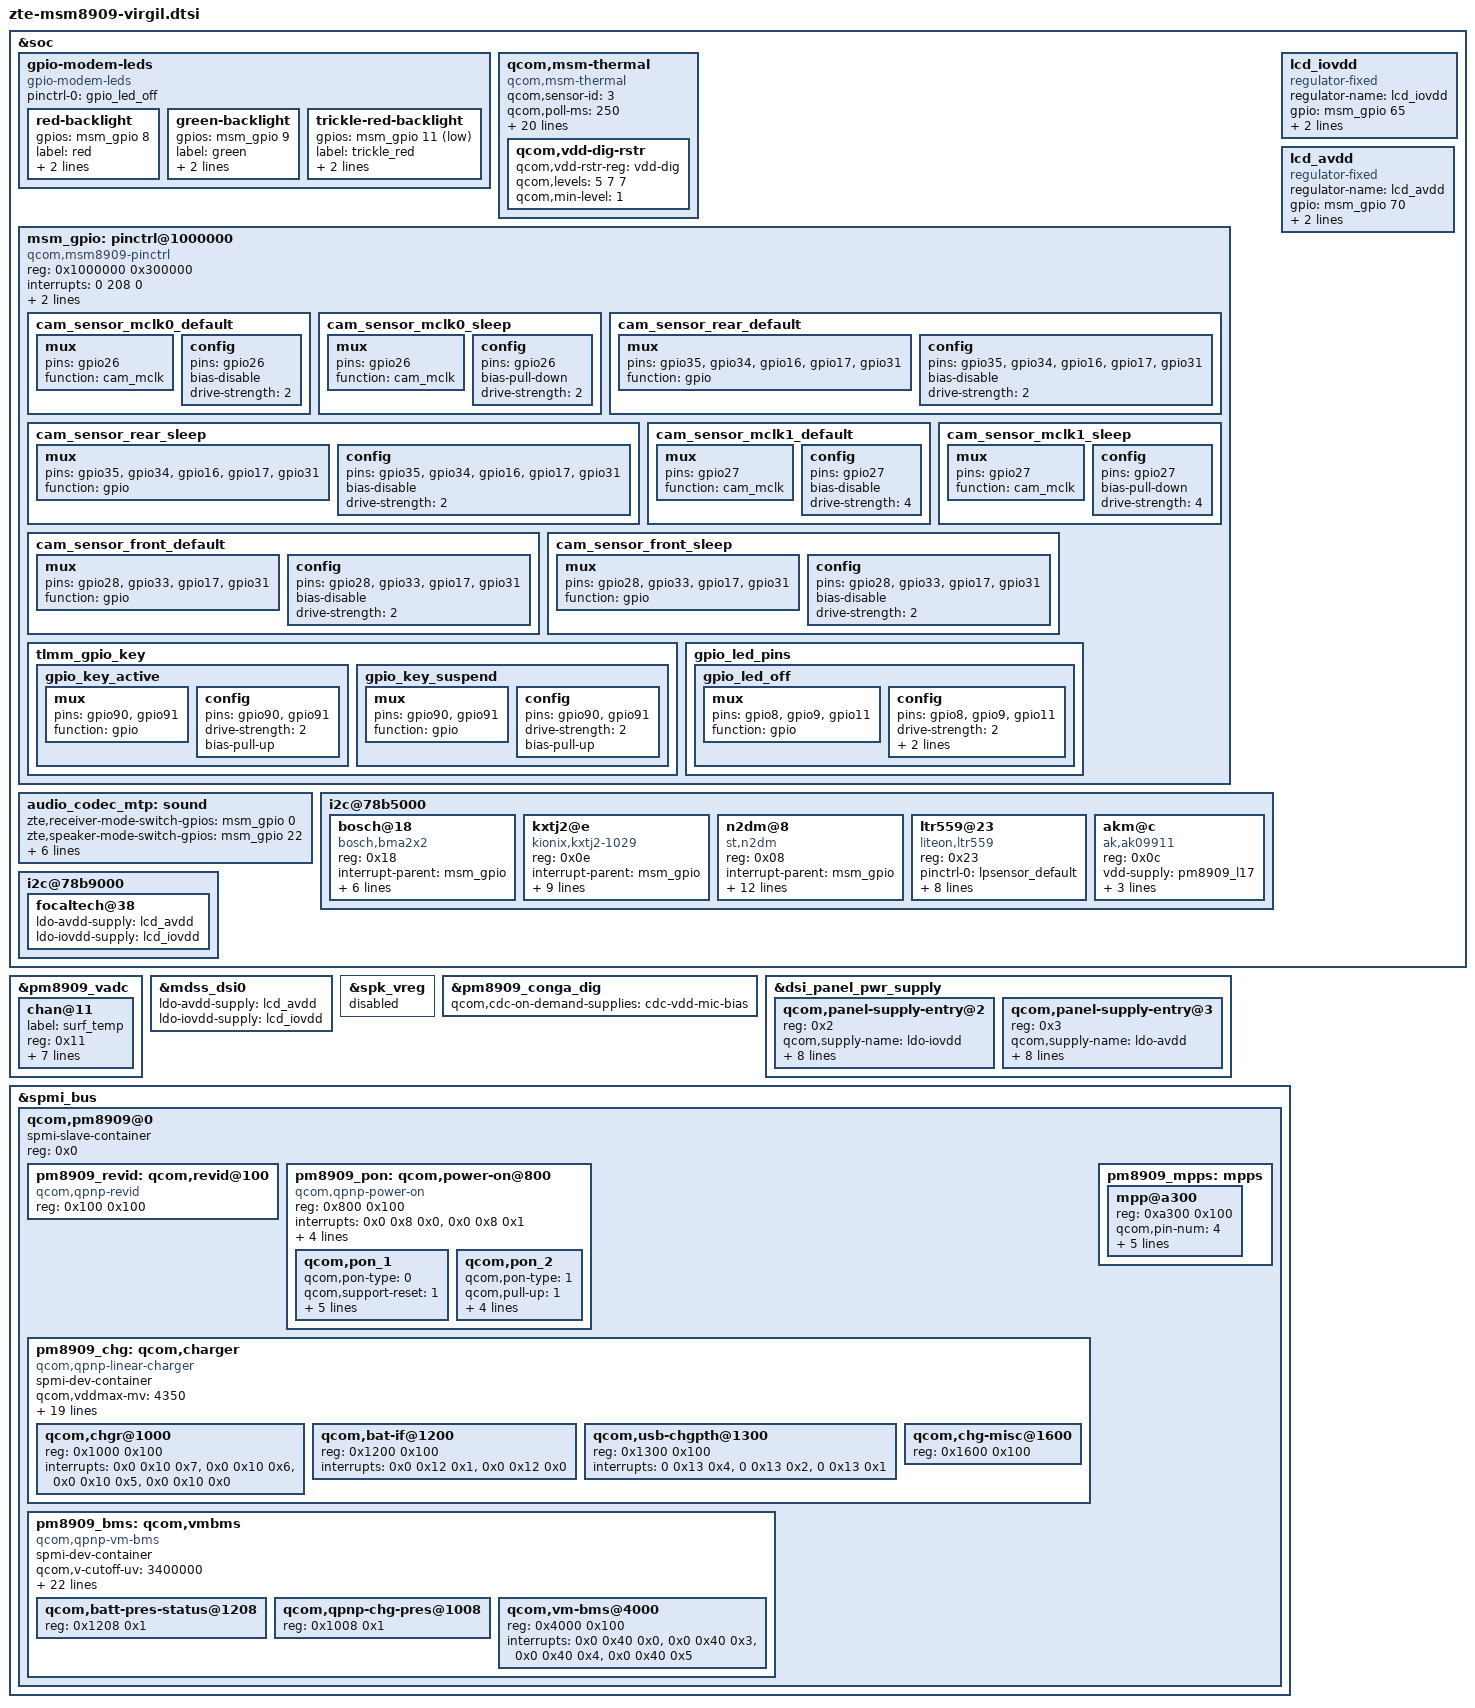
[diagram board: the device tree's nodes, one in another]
#include "virgil/zte-helitai-hsd-jd9161-4p0-fwvga-video.dtsi"
#include "virgil/zte-lianchuang-ili9806e-hsd-4p0-fwvga-video.dtsi"
#include "virgil/zte-dsi-panel-zhongguangdian-st7701s-ctc-4p0-480p-video.dtsi"
#include "touch-key-backlight-virgil.dtsi"
&soc {
	/*ZTE_MODIFY, add leds gpio conrol, start*/
	gpio-modem-leds {
		compatible = "gpio-modem-leds";
		status = "okay";
		pinctrl-names = "default";
		pinctrl-0 = <&gpio_led_off>;

		red-backlight {
			gpios = <&msm_gpio 8 0>;
			label = "red";
			linux,default-trigger = "none";
			retain-state-suspended;
		};
		green-backlight {
			gpios = <&msm_gpio 9 0>;
			label = "green";
			linux,default-trigger = "none";
			retain-state-suspended;
		};
		trickle-red-backlight {
			gpios = <&msm_gpio 11 1>; /*active low*/
			label = "trickle_red";
			linux,default-trigger = "none";
			retain-state-suspended;
		};
	};
	/*ZTE_MODIFY, add leds gpio conrol, end*/
	qcom,msm-thermal {
		compatible = "qcom,msm-thermal";
		qcom,sensor-id = <3>;
		qcom,poll-ms = <250>;
		qcom,limit-temp = <90>;
		qcom,temp-hysteresis = <10>;
		qcom,freq-step = <2>;
		qcom,core-limit-temp = <80>;
		qcom,core-temp-hysteresis = <10>;
		qcom,hotplug-temp = <97>;
		qcom,hotplug-temp-hysteresis = <12>;
		qcom,freq-mitigation-temp = <97>;
		qcom,freq-mitigation-temp-hysteresis = <12>;
		qcom,freq-mitigation-value = <800000>;
		qcom,online-hotplug-core;
		qcom,therm-reset-temp = <115>;
		qcom,disable-cx-phase-ctrl;
		qcom,disable-gfx-phase-ctrl;
		qcom,disable-vdd-mx;
		qcom,disable-psm;
		qcom,disable-ocr;
		qcom,vdd-restriction-temp = <5>;
		qcom,vdd-restriction-temp-hysteresis = <10>;
		vdd-dig-supply = <&pm8909_s1_floor_corner>;

		qcom,vdd-dig-rstr{
			qcom,vdd-rstr-reg = "vdd-dig";
			qcom,levels = <5 7 7>; /* Nominal, Super Turbo, Super Turbo */
			qcom,min-level = <1>; /* No Request */
		};
	};
	/*ZTE yuxin add for camera gpios 20171023,begin*/
	msm_gpio: pinctrl@1000000 {
		compatible = "qcom,msm8909-pinctrl";
		reg = <0x1000000 0x300000>;
		interrupts = <0 208 0>;
		gpio-controller;
		#gpio-cells = <2>;
		interrupt-controller;
		#interrupt-cells = <2>;
		/* sensors */
		cam_sensor_mclk0_default: cam_sensor_mclk0_default {
			/* MCLK0 */
			mux {
				/* CLK, DATA */
				pins = "gpio26";
				function = "cam_mclk";
			};

			config {
				pins = "gpio26";
				bias-disable; /* No PULL */
				drive-strength = <2>; /* 2 MA */
			};
		};

		cam_sensor_mclk0_sleep: cam_sensor_mclk0_sleep {
			/* MCLK0 */
			mux {
				/* CLK, DATA */
				pins = "gpio26";
				function = "cam_mclk";
			};

			config {
				pins = "gpio26";
				bias-pull-down; /* PULL DOWN */
				drive-strength = <2>; /* 2 MA */
			};
		};

		cam_sensor_rear_default: cam_sensor_rear_default {
			/* RESET, STANDBY */
			mux {
				pins = "gpio35","gpio34","gpio16","gpio17","gpio31";
				function = "gpio";
			};

			config {
				pins = "gpio35","gpio34","gpio16","gpio17","gpio31";
				bias-disable; /* No PULL */
				drive-strength = <2>; /* 2 MA */
			};
		};

		cam_sensor_rear_sleep: cam_sensor_rear_sleep {
			/* RESET, STANDBY */
			mux {
				pins = "gpio35","gpio34","gpio16","gpio17","gpio31";
				function = "gpio";
			};

			config {
				pins = "gpio35","gpio34","gpio16","gpio17","gpio31";
				bias-disable; /* No PULL */
				drive-strength = <2>; /* 2 MA */
			};
		};

		cam_sensor_mclk1_default: cam_sensor_mclk1_default {
			/* MCLK1 */
			mux {
				/* CLK, DATA */
				pins = "gpio27";
				function = "cam_mclk";
			};

			config {
				pins = "gpio27";
				bias-disable; /* No PULL */
				drive-strength = <4>; /* 4 MA */
			};
		};

		cam_sensor_mclk1_sleep: cam_sensor_mclk1_sleep {
			/* MCLK1 */
			mux {
				/* CLK, DATA */
				pins = "gpio27";
				function = "cam_mclk";
			};

			config {
				pins = "gpio27";
				bias-pull-down; /* PULL DOWN */
				drive-strength = <4>; /* 4 MA */
			};
		};

		cam_sensor_front_default: cam_sensor_front_default {
			/* RESET, STANDBY */
			mux {
				pins = "gpio28","gpio33","gpio17","gpio31";
				function = "gpio";
			};

			config {
				pins = "gpio28","gpio33","gpio17","gpio31";
				bias-disable; /* No PULL */
				drive-strength = <2>; /* 2 MA */
			};
		};

		cam_sensor_front_sleep: cam_sensor_front_sleep {
			/* RESET, STANDBY */
			mux {
				pins = "gpio28","gpio33","gpio17","gpio31";
				function = "gpio";
			};

			config {
				pins = "gpio28","gpio33","gpio17","gpio31";
				bias-disable; /* No PULL */
				drive-strength = <2>; /* 2 MA */
			};
		};
	tlmm_gpio_key {
			gpio_key_active: gpio_key_active {
				mux {
					pins = "gpio90", "gpio91";
					function = "gpio";
				};

				config {
					pins = "gpio90", "gpio91";
					drive-strength = <2>;
					bias-pull-up;
				};
			};

			gpio_key_suspend: gpio_key_suspend {
				mux {
					pins = "gpio90", "gpio91";
					function = "gpio";
				};

				config {
					pins = "gpio90", "gpio91";
					drive-strength = <2>;
					bias-pull-up;
				};
			};
		};
	};
	/*ZTE yuxin add for camera gpios 20171023,end*/
	/*zte yangliu add it for AW87318 begin*/
	audio_codec_mtp: sound {
		zte,receiver-mode-switch-gpios = <&msm_gpio 0 0x0>;
		zte,speaker-mode-switch-gpios = <&msm_gpio 22 0x0>;
		qcom,msm-mbhc-gnd-swh = <1>;
		qcom,msm-gpios =
			"pri_i2s";
		qcom,pinctrl-names =
			"all_off",
			"pri_i2s_act";
		pinctrl-names =
			"all_off",
			"pri_i2s_act";
		pinctrl-0 = <&cdc_pdm_lines_sus>;
		pinctrl-1 = <&cdc_pdm_lines_act>;
		/delete-property/ pinctrl-2;
		/delete-property/ pinctrl-3;
		/delete-property/ qcom,cdc-us-euro-gpios;
		qcom,msm-micbias2-ext-cap;
		/delete-property/ qcom,msm-spk-ext-boost;
	};
	/*zte yangliu add it for AW87318 end*/

	i2c@78b5000 { /* BLSP1 QUP1 */
		bosch@18 { /* Accelerometer sensor */
			compatible = "bosch,bma2x2";
			reg = <0x18>;
			interrupt-parent = <&msm_gpio>;
			interrupts = <96 0x2002>;
			vdd-supply = <&pm8909_l17>;
			vio-supply = <&pm8909_l6>;
			bosch,init-interval = <200>;
			bosch,place = <7>;
			bosch,gpio-int1 = <&msm_gpio 96 0x2002>;
			/*bosch,gpio-int2 = <&msm_gpio 65 0x2002>;*/
		};

		kxtj2@e {
			compatible = "kionix,kxtj2-1029";
			reg = <0x0e>;
			interrupt-parent = <&msm_gpio>;
			/*interrupts = <96 0x2>;*/
			vddhold-supply = <&pm8909_l17>;
			vdd-supply = <&pm8909_l17>;
			vio-supply = <&pm8909_l6>;
			kionix,min_interval = <5>;
			kionix,poll_interval = <100>;
			kionix,accel_direction = <7>;
			kionix,accel_irq_use_drdy = <0>;
			/*0 is 12BIT,	1 is 8BIT,	2 is 6BIT*/
			kionix,accel_res = <0>;
			/*0 is 2g,	1 is 4g,	2 is 6g,	3 is 8g*/
			kionix,accel_g_range =	<0>;
		};

		n2dm@8 {
			compatible = "st,n2dm";
			reg = <0x08>;
			interrupt-parent = <&msm_gpio>;
			/*interrupts = <96 0x2>;*/
			vddhold-supply = <&pm8909_l17>;
			vdd-supply = <&pm8909_l17>;
			vddio-supply = <&pm8909_l6>;
			n2dm,min_interval = <1>;
			n2dm,poll_interval = <100>;
			n2dm,axis-map-x = <1>;
			n2dm,axis-map-y = <0>;
			n2dm,axis-map-z = <2>;
			n2dm,negate-x;
			n2dm,negate-y;
			n2dm,negate-z;
			/*0 is 2g,	16 is 4g,	32 is 8g,	48 is 16g*/
			n2dm,fs-range = <0>;
		};

		ltr559@23 {
			compatible = "liteon,ltr559";
			reg = <0x23>;
			pinctrl-names = "lpsensor_default", "lpsensor_sleep";
			pinctrl-0 = <&lpsensor_default>;
			pinctrl-1 = <&lpsensor_sleep>;
			interrupt-parent = <&msm_gpio>;
			interrupts = <94 0x2002>;
			vdd-supply = <&pm8909_l17>;
			vio-supply = <&pm8909_l6>;
			liteon,irq-gpio = <&msm_gpio 94 0x2002>;
			liteon,highthr = <1500>;
			liteon,lowthr = <1200>;
		};

		akm@c {
			compatible = "ak,ak09911";
			reg = <0x0c>;
			vdd-supply = <&pm8909_l17>;
			vio-supply = <&pm8909_l6>;
			akm,layout = <0x2>;
			akm,auto-report;
		};

	};
};
&pm8909_vadc {
		chan@11 {
		label = "surf_temp";
		reg = <0x11>;
		qcom,decimation = <0>;
		qcom,pre-div-channel-scaling = <0>;
		qcom,calibration-type = "ratiometric";
		qcom,scale-function = <2>;
		qcom,hw-settle-time = <2>;
		qcom,fast-avg-setup = <0>;
		qcom,vadc-thermal-node;
	};
};

&msm_gpio {
	/*ZTE_MODIFY, add leds gpio conrol, start*/
	gpio_led_pins {
		gpio_led_off: gpio_led_off {
			mux {
				pins = "gpio8", "gpio9", "gpio11";
				function = "gpio";
			};

			config {
				pins = "gpio8", "gpio9", "gpio11";
				drive-strength = <2>;
				bias-disable;
				output-low;
			};
		};
	};
	/*ZTE_MODIFY, add leds gpio conrol, end*/
};

/*yangchaofeng add for config panel*/
&soc {
	lcd_iovdd: lcd_iovdd {
		status = "okay";
		compatible = "regulator-fixed";
		regulator-name = "lcd_iovdd";
		gpio = <&msm_gpio 65 0>;
		enable-active-high;
		regulator-boot-on;
	};

	lcd_avdd: lcd_avdd {
		status = "okay";
		compatible = "regulator-fixed";
		regulator-name = "lcd_avdd";
		gpio = <&msm_gpio 70 0>;
		enable-active-high;
		regulator-boot-on;
	};

	i2c@78b9000 {
		focaltech@38{
			ldo-avdd-supply = <&lcd_avdd>;
			ldo-iovdd-supply = <&lcd_iovdd>;
		};
	};
};
&mdss_dsi0 {
	/*zte,disp_avdd_en_gpio = <&msm_gpio 70 0x00>;*/
	/*zte,disp_iovdd_en_gpio = <&msm_gpio 65 0x00>;*/
	ldo-avdd-supply = <&lcd_avdd>;
	ldo-iovdd-supply = <&lcd_iovdd>;
	/delete-property/ qcom,platform-bklight-en-gpio;
};


&spk_vreg {
	status = "disabled";
};
&pm8909_conga_dig {
	/delete-property/ cdc-vdd-spkdrv-supply;
	/delete-property/ qcom,cdc-vdd-spkdrv-voltage;
	/delete-property/ qcom,cdc-vdd-spkdrv-current;
	qcom,cdc-on-demand-supplies = "cdc-vdd-mic-bias";
};

&dsi_panel_pwr_supply {
	qcom,panel-supply-entry@2 {
		reg = <0x2>;
		qcom,supply-name = "ldo-iovdd";
		qcom,supply-min-voltage = <0>;
		qcom,supply-max-voltage = <0>;
		qcom,supply-enable-load = <0>;
		qcom,supply-disable-load = <0>;
		qcom,supply-pre-on-sleep = <1>;
		qcom,supply-post-on-sleep = <1>;
		qcom,supply-pre-off-sleep = <1>;
		qcom,supply-post-off-sleep = <1>;
	};

	qcom,panel-supply-entry@3 {
		reg = <0x3>;
		qcom,supply-name = "ldo-avdd";
		qcom,supply-min-voltage = <0>;
		qcom,supply-max-voltage = <0>;
		qcom,supply-enable-load = <0>;
		qcom,supply-disable-load = <0>;
		qcom,supply-pre-on-sleep = <1>;
		qcom,supply-post-on-sleep = <1>;
		qcom,supply-pre-off-sleep = <1>;
		qcom,supply-post-off-sleep = <1>;
	};
};

&spmi_bus {

	qcom,pm8909@0 {
		spmi-slave-container;
		reg = <0x0>;
		#address-cells = <1>;
		#size-cells = <1>;

		pm8909_revid: qcom,revid@100 {
			compatible = "qcom,qpnp-revid";
			reg = <0x100 0x100>;
		};

		pm8909_pon: qcom,power-on@800 {
			compatible = "qcom,qpnp-power-on";
			reg = <0x800 0x100>;
			interrupts = <0x0 0x8 0x0>,
				     <0x0 0x8 0x1>;
			interrupt-names = "kpdpwr", "resin";
			qcom,pon-dbc-delay = <15625>;
			qcom,system-reset;
			qcom,clear-warm-reset;
			qcom,store-hard-reset-reason;

			qcom,pon_1 {
				qcom,pon-type = <0>;
				qcom,support-reset = <1>;
				qcom,pull-up = <1>;
				qcom,s1-timer = <10256>;
				qcom,s2-timer = <2000>;
				qcom,s2-type = <7>;
				linux,code = <116>;
			};

			qcom,pon_2 {
				qcom,pon-type = <1>;
				qcom,pull-up = <1>;
				/*linux,code = <114>;*/
				qcom,support-reset = <1>;
				qcom,s1-timer = <32>;
				qcom,s2-timer = <10>;
				qcom,s2-type = <1>;
			};
		};

		pm8909_chg: qcom,charger {
			spmi-dev-container;
			compatible = "qcom,qpnp-linear-charger";
			#address-cells = <1>;
			#size-cells = <1>;

			qcom,vddmax-mv = <4350>;
			qcom,vddsafe-mv = <4380>;
			qcom,vinmin-mv = <4450>;
			qcom,ibatsafe-ma = <1000>;
			qcom,thermal-mitigation = <1440 300 90 0>;
			qcom,cool-bat-decidegc = <100>;
			qcom,warm-bat-decidegc = <450>;
			qcom,cold-bat-decidegc = <10>;
			qcom,hot-bat-decidegc = <550>;
			qcom,cool-bat-mv = <4350>;
			qcom,warm-bat-mv = <4100>;
			qcom,ibatmax-warm-ma = <500>;
			qcom,ibatmax-cool-ma = <500>;
			qcom,batt-hot-percentage = <25>;
			qcom,batt-cold-percentage = <80>;
			qcom,tchg-mins = <1536>;
			qcom,chg-vadc = <&pm8909_vadc>;
			qcom,chg-adc_tm = <&pm8909_adc_tm>;
			qcom,bpd-detection = "bpd_thm";
			qcom,disable-vbatdet-based-recharge;
			status = "ok";

			qcom,chgr@1000 {
				reg = <0x1000 0x100>;
				interrupts =	<0x0 0x10 0x7>,
						<0x0 0x10 0x6>,
						<0x0 0x10 0x5>,
						<0x0 0x10 0x0>;
				interrupt-names =	"chg-done",
							"chg-failed",
							"fast-chg-on",
							"vbat-det-lo";
			};

			qcom,bat-if@1200 {
				reg = <0x1200 0x100>;
				interrupts =	<0x0 0x12 0x1>,
						<0x0 0x12 0x0>;
				interrupt-names =	"bat-temp-ok",
							"batt-pres";
			};

			qcom,usb-chgpth@1300 {
				reg = <0x1300 0x100>;
				interrupts =	<0 0x13 0x4>,
						<0 0x13 0x2>,
						<0 0x13 0x1>;
				interrupt-names =	"usb-over-temp",
							"chg-gone",
							"usbin-valid";
			};

			qcom,chg-misc@1600 {
				reg = <0x1600 0x100>;
			};
		};
		pm8909_mpps: mpps {
		mpp@a300 {
				reg = <0xa300 0x100>;
				qcom,pin-num = <4>;
				qcom,mode = <1>;
				qcom,invert = <0>;
				qcom,src-sel = <4>;
				qcom,vin-sel = <3>;
				qcom,master-en = <1>;
			};
		};

		pm8909_bms: qcom,vmbms {
			spmi-dev-container;
			compatible = "qcom,qpnp-vm-bms";
			#address-cells = <1>;
			#size-cells = <1>;
			status = "ok";

			qcom,v-cutoff-uv = <3400000>;
			qcom,max-voltage-uv = <4350000>;
			qcom,r-conn-mohm = <16>;
			qcom,shutdown-soc-valid-limit = <100>;
			qcom,low-soc-calculate-soc-threshold = <15>;
			qcom,low-voltage-calculate-soc-ms = <1000>;
			qcom,low-soc-calculate-soc-ms = <5000>;
			qcom,calculate-soc-ms = <20000>;
			qcom,volatge-soc-timeout-ms = <60000>;
			qcom,low-voltage-threshold = <3450000>;
			qcom,s3-ocv-tolerence-uv = <1200>;
			qcom,s2-fifo-length = <5>;
			qcom,low-soc-fifo-length = <2>;
			qcom,bms-vadc = <&pm8909_vadc>;
			qcom,bms-adc_tm = <&pm8909_adc_tm>;
			qcom,pmic-revid = <&pm8909_revid>;

			qcom,force-s3-on-suspend;
			qcom,force-s2-in-charging;
			qcom,report-charger-eoc;
			qcom,use-reported-soc;
			qcom,resume-soc = <97>;
			qcom,use-poweroff-soc;
			qcom,force-bms-active-on-charger;

			qcom,batt-pres-status@1208 {
				reg = <0x1208 0x1>;
			};

			qcom,qpnp-chg-pres@1008 {
				reg = <0x1008 0x1>;
			};

			qcom,vm-bms@4000 {
				reg = <0x4000 0x100>;
				interrupts =	<0x0 0x40 0x0>,
						<0x0 0x40 0x3>,
						<0x0 0x40 0x4>,
						<0x0 0x40 0x5>;

				interrupt-names = "leave_cv",
						  "ocv_thr",
						  "fifo_update_done",
						  "fsm_state_change";
			};
		};
	};
};

